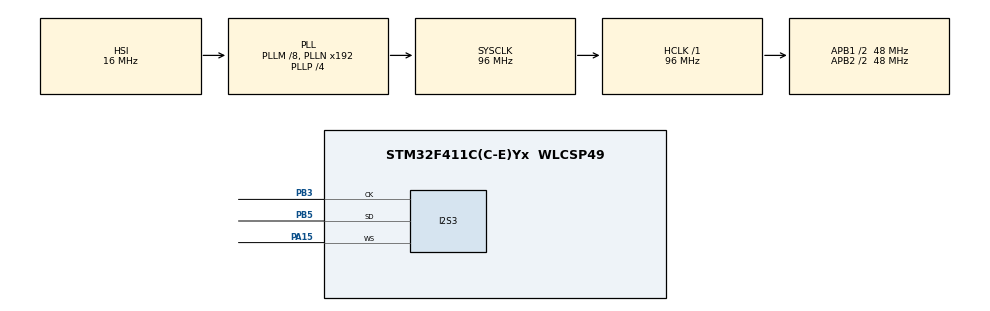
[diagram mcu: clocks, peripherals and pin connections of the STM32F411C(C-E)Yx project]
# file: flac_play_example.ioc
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Mcu.Family=STM32F4
Dma.SPI3_TX.0.FIFOMode=DMA_FIFOMODE_DISABLE
RCC.VDD_VALUE=1.8
Dma.SPI3_TX.0.Priority=DMA_PRIORITY_HIGH
Dma.SPI3_TX.0.MemInc=DMA_MINC_ENABLE
I2S3.FullDuplexMode=I2S_FULLDUPLEXMODE_DISABLE
RCC.CortexFreq_Value=96000000
FREERTOS.Tasks01=defaultTask,24,128,StartDefaultTask,As weak,NULL,Dynamic,NULL,NULL
FREERTOS.configCHECK_FOR_STACK_OVERFLOW=2
FREERTOS.configUSE_TICKLESS_IDLE=0
Dma.SPI3_TX.0.PeriphDataAlignment=DMA_PDATAALIGN_HALFWORD
RCC.APB1CLKDivider=RCC_HCLK_DIV2
I2S3.DataFormat=I2S_DATAFORMAT_16B_EXTENDED
FREERTOS.configUSE_TASK_NOTIFICATIONS=1
RCC.PWR_Regulator_Voltage_Scale=PWR_REGULATOR_VOLTAGE_SCALE1
RCC.SYSCLKSource=RCC_SYSCLKSOURCE_PLLCLK
ProjectManager.StackSize=0x400
VP_FREERTOS_VS_CMSIS_V2.Mode=CMSIS_V2
FREERTOS.configUSE_IDLE_HOOK=1
ProjectManager.TargetToolchain=STM32CubeIDE
NVIC.DMA1_Stream5_IRQn=true\:4\:0\:true\:false\:true\:true\:false\:true
RCC.HCLKFreq_Value=96000000
RCC.APB2TimFreq_Value=96000000
I2S3.VirtualMode=I2S_MODE_MASTER
FREERTOS.configUSE_MALLOC_FAILED_HOOK=1
Dma.SPI3_TX.0.PeriphInc=DMA_PINC_DISABLE
RCC.LSE_VALUE=32768
Dma.SPI3_TX.0.Direction=DMA_MEMORY_TO_PERIPH
RCC.AHBFreq_Value=96000000
RCC.HSE_VALUE=8000000
I2S3.AudioFreq=I2S_AUDIOFREQ_48K
PB3.Mode=Half_Duplex_Master
board=custom
RCC.VCOOutputFreq_Value=384000000
PA15.Mode=Half_Duplex_Master
I2S3.ErrorAudioFreq=0.8 %
RCC.APB2Freq_Value=48000000
VP_SYS_VS_tim1.Mode=TIM1
PB5.Mode=Half_Duplex_Master
Dma.SPI3_TX.0.Instance=DMA1_Stream5
Mcu.Name=STM32F411C(C-E)Yx
FREERTOS.configTOTAL_HEAP_SIZE=40960
Dma.SPI3_TX.0.MemDataAlignment=DMA_MDATAALIGN_HALFWORD
RCC.48MHZClocksFreq_Value=96000000
PB3.Signal=I2S3_CK
RCC.SYSCLKFreq_VALUE=96000000
FREERTOS.configLIBRARY_MAX_SYSCALL_INTERRUPT_PRIORITY=4
Mcu.Package=WLCSP49
PB5.Signal=I2S3_SD
NVIC.TimeBase=TIM1_UP_TIM10_IRQn
Dma.SPI3_TX.0.Mode=DMA_CIRCULAR
NVIC.TimeBaseIP=TIM1
PA14.Signal=SYS_JTCK-SWCLK
PA15.Signal=I2S3_WS
ProjectManager.HeapSize=0x200
NVIC.TIM1_UP_TIM10_IRQn=true\:0\:0\:false\:false\:true\:false\:false\:true
RCC.HSI_VALUE=16000000
RCC.PLLP=RCC_PLLP_DIV4
NVIC.PriorityGroup=NVIC_PRIORITYGROUP_4
RCC.APB2CLKDivider=RCC_HCLK_DIV2
I2S3.RealAudioFreq=48.387 KHz
RCC.PLLM=8
RCC.APB1TimFreq_Value=96000000
FREERTOS.configUSE_TICK_HOOK=0
I2S3.Instance=SPI$Index
Dma.Request0=SPI3_TX
RCC.APB1Freq_Value=48000000
RCC.PLLI2SN=96
RCC.PLLI2SM=8

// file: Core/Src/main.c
/* USER CODE BEGIN Header */
/**
  ******************************************************************************
  * @file           : main.c
  * @brief          : Main program body
  ******************************************************************************
  * @attention
  *
  * <h2><center>&copy; Copyright (c) 2020 STMicroelectronics.
  * All rights reserved.</center></h2>
  *
  * This software component is licensed by ST under Ultimate Liberty license
  * SLA0044, the "License"; You may not use this file except in compliance with
  * the License. You may obtain a copy of the License at:
  *                             www.st.com/SLA0044
  *
  ******************************************************************************
  */
/* USER CODE END Header */
#include "main.h"
#include "cmsis_os.h"
#include "dma.h"
#include "i2s.h"
#include "gpio.h"

/* USER CODE BEGIN Includes */
#include "rtos_config.h"

#include "rtos.h"          //RTOS routines

#include "i2s/i2s_peri.h"
#include "audio_clip.h"

/* USER CODE END Includes */

void SystemClock_Config(void);
void MX_FREERTOS_Init(void);

int main(void)
{

  /* MCU Configuration--------------------------------------------------------*/

  /* Reset of all peripherals, Initializes the Flash interface and the Systick. */
  HAL_Init();

  /* Configure the system clock */
  SystemClock_Config();

  /* Initialize all configured peripherals */
  MX_GPIO_Init();
  MX_DMA_Init();
  MX_I2S3_Init();

  /* Init scheduler */
  osKernelInitialize();  /* Call init function for freertos objects (in freertos.c) */
  MX_FREERTOS_Init();
  /* Start scheduler */
  osKernelStart();

  /* We should never get here as control is now taken by the scheduler */
  /* Infinite loop */
  while (1)
  {

  }
}

void SystemClock_Config(void)
{
  RCC_OscInitTypeDef RCC_OscInitStruct = {0};
  RCC_ClkInitTypeDef RCC_ClkInitStruct = {0};
  RCC_PeriphCLKInitTypeDef PeriphClkInitStruct = {0};

  /** Configure the main internal regulator output voltage
  */
  __HAL_RCC_PWR_CLK_ENABLE();
  __HAL_PWR_VOLTAGESCALING_CONFIG(PWR_REGULATOR_VOLTAGE_SCALE1);
  /** Initializes the RCC Oscillators according to the specified parameters
  * in the RCC_OscInitTypeDef structure.
  */
  RCC_OscInitStruct.OscillatorType = RCC_OSCILLATORTYPE_HSI;
  RCC_OscInitStruct.HSIState = RCC_HSI_ON;
  RCC_OscInitStruct.HSICalibrationValue = RCC_HSICALIBRATION_DEFAULT;
  RCC_OscInitStruct.PLL.PLLState = RCC_PLL_ON;
  RCC_OscInitStruct.PLL.PLLSource = RCC_PLLSOURCE_HSI;
  RCC_OscInitStruct.PLL.PLLM = 8;
  RCC_OscInitStruct.PLL.PLLN = 192;
  RCC_OscInitStruct.PLL.PLLP = RCC_PLLP_DIV4;
  RCC_OscInitStruct.PLL.PLLQ = 4;
  if (HAL_RCC_OscConfig(&RCC_OscInitStruct) != HAL_OK)
  {
    Error_Handler();
  }
  /** Initializes the CPU, AHB and APB buses clocks
  */
  RCC_ClkInitStruct.ClockType = RCC_CLOCKTYPE_HCLK|RCC_CLOCKTYPE_SYSCLK
                              |RCC_CLOCKTYPE_PCLK1|RCC_CLOCKTYPE_PCLK2;
  RCC_ClkInitStruct.SYSCLKSource = RCC_SYSCLKSOURCE_PLLCLK;
  RCC_ClkInitStruct.AHBCLKDivider = RCC_SYSCLK_DIV1;
  RCC_ClkInitStruct.APB1CLKDivider = RCC_HCLK_DIV2;
  RCC_ClkInitStruct.APB2CLKDivider = RCC_HCLK_DIV2;

  if (HAL_RCC_ClockConfig(&RCC_ClkInitStruct, FLASH_LATENCY_5) != HAL_OK)
  {
    Error_Handler();
  }
  PeriphClkInitStruct.PeriphClockSelection = RCC_PERIPHCLK_I2S;
  PeriphClkInitStruct.PLLI2S.PLLI2SN = 96;
  PeriphClkInitStruct.PLLI2S.PLLI2SM = 8;
  PeriphClkInitStruct.PLLI2S.PLLI2SR = 2;
  if (HAL_RCCEx_PeriphCLKConfig(&PeriphClkInitStruct) != HAL_OK)
  {
    Error_Handler();
  }
}

 /**
  * @brief  Period elapsed callback in non blocking mode
  * @note   This function is called  when TIM1 interrupt took place, inside
  * HAL_TIM_IRQHandler(). It makes a direct call to HAL_IncTick() to increment
  * a global variable "uwTick" used as application time base.
  * @param  htim : TIM handle
  * @retval None
  */
void HAL_TIM_PeriodElapsedCallback(TIM_HandleTypeDef *htim)
{
  if (htim->Instance == TIM1) {
    HAL_IncTick();
  }
}

void Error_Handler(void)
{
}

/************************ (C) COPYRIGHT STMicroelectronics *****END OF FILE****/

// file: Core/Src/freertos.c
/* USER CODE BEGIN Header */
/**
  ******************************************************************************
  * File Name          : freertos.c
  * Description        : Code for freertos applications
  ******************************************************************************
  * @attention
  *
  * <h2><center>&copy; Copyright (c) 2020 STMicroelectronics.
  * All rights reserved.</center></h2>
  *
  * This software component is licensed by ST under Ultimate Liberty license
  * SLA0044, the "License"; You may not use this file except in compliance with
  * the License. You may obtain a copy of the License at:
  *                             www.st.com/SLA0044
  *
  ******************************************************************************
  */
/* USER CODE END Header */

#include "FreeRTOS.h"
#include "task.h"
#include "main.h"
#include "cmsis_os.h"

/* USER CODE BEGIN Includes */
#include "rtos_config.h"

#include "loop.h"
/* USER CODE END Includes */

/* USER CODE BEGIN Variables */

TaskHandle_t acl_task;

/* USER CODE END Variables */
/* Definitions for defaultTask */
osThreadId_t defaultTaskHandle;
const osThreadAttr_t defaultTask_attributes = {
  .name = "defaultTask",
  .stack_size = 128 * 4,
  .priority = (osPriority_t) osPriorityNormal,
};

void StartDefaultTask(void *argument);

void MX_FREERTOS_Init(void); /* (MISRA C 2004 rule 8.1) */

/* Hook prototypes */
void vApplicationIdleHook(void);
void vApplicationStackOverflowHook(xTaskHandle xTask, signed char *pcTaskName);
void vApplicationMallocFailedHook(void);

/* USER CODE BEGIN 2 */
__weak void vApplicationIdleHook( void )
{
   /* vApplicationIdleHook() will only be called if configUSE_IDLE_HOOK is set
   to 1 in FreeRTOSConfig.h. It will be called on each iteration of the idle
   task. It is essential that code added to this hook function never attempts
   to block in any way (for example, call xQueueReceive() with a block time
   specified, or call vTaskDelay()). If the application makes use of the
   vTaskDelete() API function (as this demo application does) then it is also
   important that vApplicationIdleHook() is permitted to return to its calling
   function, because it is the responsibility of the idle task to clean up
   memory allocated by the kernel to any task that has since been deleted. */

}
/* USER CODE END 2 */

/* USER CODE BEGIN 4 */
__weak void vApplicationStackOverflowHook(xTaskHandle xTask, signed char *pcTaskName)
{
   /* Run time stack overflow checking is performed if
   configCHECK_FOR_STACK_OVERFLOW is defined to 1 or 2. This hook function is
   called if a stack overflow is detected. */

	while(1);
}
/* USER CODE END 4 */

/* USER CODE BEGIN 5 */
void vApplicationMallocFailedHook(void)
{
	while(1);
   /* vApplicationMallocFailedHook() will only be called if
   configUSE_MALLOC_FAILED_HOOK is set to 1 in FreeRTOSConfig.h. It is a hook
   function that will get called if a call to pvPortMalloc() fails.
   pvPortMalloc() is called internally by the kernel whenever a task, queue,
   timer or semaphore is created. It is also called by various parts of the
   demo application. If heap_1.c or heap_2.c are used, then the size of the
   heap available to pvPortMalloc() is defined by configTOTAL_HEAP_SIZE in
   FreeRTOSConfig.h, and the xPortGetFreeHeapSize() API function can be used
   to query the size of free heap space that remains (although it does not
   provide information on how the remaining heap might be fragmented). */
}
/* USER CODE END 5 */

void MX_FREERTOS_Init(void) {

  /* Create the thread(s) */
  /* creation of defaultTask */
  defaultTaskHandle = osThreadNew(StartDefaultTask, NULL, &defaultTask_attributes);

  /* USER CODE BEGIN RTOS_THREADS */

  //Stop default task
  osThreadSuspend(defaultTaskHandle);
  osThreadTerminate(defaultTaskHandle);

  //Start Audio Clip Play loop (found in loop.c)
  rtos_createThread(&acl_task, ACL_RTOS_PRIORITY, ACL_STACKSIZE,
                      audioClipLoop, "Audio Clip Play Loop", NULL);

  /* USER CODE END RTOS_THREADS */

}

__weak void StartDefaultTask(void *argument)
{
  for(;;)
  {
    osDelay(1);
  }
}

/************************ (C) COPYRIGHT STMicroelectronics *****END OF FILE****/
